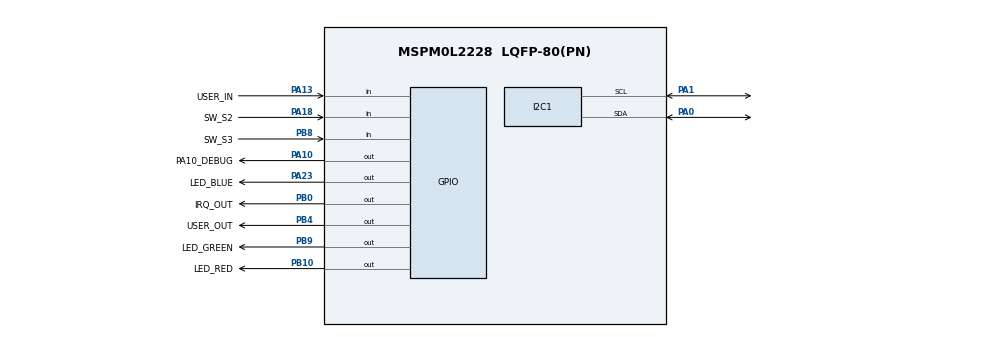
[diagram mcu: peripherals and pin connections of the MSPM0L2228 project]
//@cliArgs --device "MSPM0L222X" --package "LQFP-80(PN)" --part "Default"
//@v2CliArgs --device "MSPM0L2228" --package "LQFP-80(PN)"
// @cliArgs --board /ti/boards/LP_MSPM0L2228 --rtos nortos

/**
 * Import the modules used in this configuration.
 */
const Board         = scripting.addModule("/ti/driverlib/Board");
const GPIO          = scripting.addModule("/ti/driverlib/GPIO", {}, false);
const GPIO1         = GPIO.addInstance();
const GPIO2         = GPIO.addInstance();
const I2C           = scripting.addModule("/ti/driverlib/I2C", {}, false);
const I2C1          = I2C.addInstance();
const SYSCTL        = scripting.addModule("/ti/driverlib/SYSCTL");
const TIMER         = scripting.addModule("/ti/driverlib/TIMER", {}, false);
const TIMER1        = TIMER.addInstance();
const ProjectConfig = scripting.addModule("/ti/project_config/ProjectConfig");

/**
 * Write custom configuration values to the imported modules.
 */
Board.configureUnused    = true;
Board.genPeriphPinFile   = true;
Board.peripheral.$assign = "DEBUGSS";
Board.genFileMod.$name   = "ti_driverlib_BoardPins0";

GPIO1.port                               = "PORTB";
GPIO1.$name                              = "GPIO_B";
GPIO1.associatedPins.create(5);
GPIO1.associatedPins[0].$name            = "LED_RED";
GPIO1.associatedPins[0].assignedPin      = "10";
GPIO1.associatedPins[0].pin.$assign      = "PB10";
GPIO1.associatedPins[1].$name            = "LED_GREEN";
GPIO1.associatedPins[1].assignedPin      = "9";
GPIO1.associatedPins[1].pin.$assign      = "PB9";
GPIO1.associatedPins[2].direction        = "INPUT";
GPIO1.associatedPins[2].internalResistor = "PULL_UP";
GPIO1.associatedPins[2].interruptEn      = true;
GPIO1.associatedPins[2].polarity         = "RISE_FALL";
GPIO1.associatedPins[2].inputFilter      = "3_CYCLES";
GPIO1.associatedPins[2].$name            = "SW_S3";
GPIO1.associatedPins[2].assignedPin      = "8";
GPIO1.associatedPins[2].pin.$assign      = "PB8";
GPIO1.associatedPins[3].$name            = "IRQ_OUT";
GPIO1.associatedPins[3].internalResistor = "PULL_UP";
GPIO1.associatedPins[3].hiZ              = "ENABLE";
GPIO1.associatedPins[3].assignedPin      = "0";
GPIO1.associatedPins[3].pin.$assign      = "PB0";
GPIO1.associatedPins[4].$name            = "USER_OUT";
GPIO1.associatedPins[4].assignedPin      = "4";
GPIO1.associatedPins[4].pin.$assign      = "PB4";

GPIO2.$name                              = "GPIO_A";
GPIO2.port                               = "PORTA";
GPIO2.associatedPins.create(4);
GPIO2.associatedPins[0].direction        = "INPUT";
GPIO2.associatedPins[0].internalResistor = "PULL_DOWN";
GPIO2.associatedPins[0].assignedPin      = "13";
GPIO2.associatedPins[0].$name            = "USER_IN";
GPIO2.associatedPins[0].inputFilter      = "8_CYCLES";
GPIO2.associatedPins[0].pin.$assign      = "PA13";
GPIO2.associatedPins[1].direction        = "INPUT";
GPIO2.associatedPins[1].interruptEn      = true;
GPIO2.associatedPins[1].polarity         = "RISE_FALL";
GPIO2.associatedPins[1].inputFilter      = "3_CYCLES";
GPIO2.associatedPins[1].assignedPin      = "18";
GPIO2.associatedPins[1].$name            = "SW_S2";
GPIO2.associatedPins[1].pin.$assign      = "PA18";
GPIO2.associatedPins[2].initialValue     = "SET";
GPIO2.associatedPins[2].$name            = "PA10_DEBUG";
GPIO2.associatedPins[2].assignedPin      = "10";
GPIO2.associatedPins[2].pin.$assign      = "PA10";
GPIO2.associatedPins[3].$name            = "LED_BLUE";
GPIO2.associatedPins[3].assignedPin      = "23";
GPIO2.associatedPins[3].pin.$assign      = "PA23";

I2C1.advControllerTXFIFOTRIG           = "BYTES_1";
I2C1.$name                             = "I2C_TARGET";
I2C1.basicEnableTarget                 = true;
I2C1.intTarget                         = ["RXFIFO_TRIGGER","START","STOP"];
I2C1.advTargetClkStretch               = false;
I2C1.advTargetTXFIFOTRIG               = "BYTES_1";
I2C1.advAnalogGlitchFilter             = "DISABLED";
I2C1.basicTargetAddress                = 0x48;
I2C1.peripheral.$assign                = "I2C0";
I2C1.peripheral.sdaPin.$assign         = "PA0";
I2C1.peripheral.sclPin.$assign         = "PA1";

SYSCTL.MFCLKEn            = true;
SYSCTL.peripheral.$assign = "SYSCTL";
scripting.suppress("Note: VBAT needs to be powered for LFCLK operation\\.", SYSCTL, "LFCLKSource");

TIMER1.timerClkSrc        = "LFCLK";
TIMER1.timerPeriod        = "1 ms";
TIMER1.$name              = "TIMG_DELAY_BLOCKING";
TIMER1.interrupts         = ["ZERO"];
TIMER1.peripheral.$assign = "TIMG0";

ProjectConfig.switchCondition = true;
scripting.suppress("Migrating requires going through the Switch Board or Device menu in the Device View section\\.", ProjectConfig, "deviceSpin");
